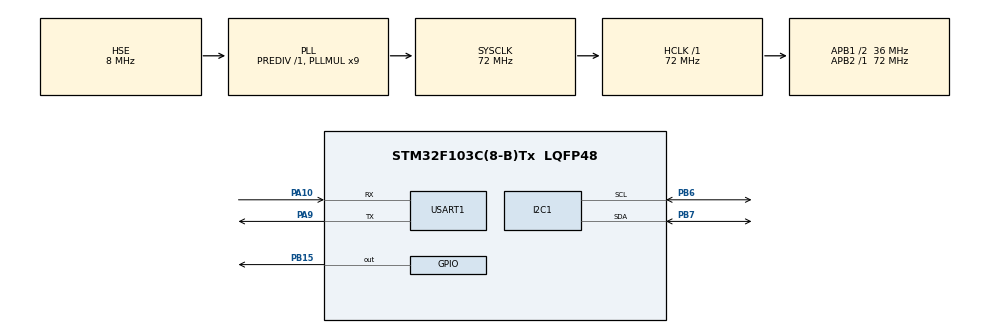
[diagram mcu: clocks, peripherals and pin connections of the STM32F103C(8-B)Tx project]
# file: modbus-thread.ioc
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Dma.I2C1_RX.0.Direction=DMA_PERIPH_TO_MEMORY
Dma.I2C1_RX.0.Instance=DMA1_Channel7
Dma.I2C1_RX.0.MemDataAlignment=DMA_MDATAALIGN_BYTE
Dma.I2C1_RX.0.MemInc=DMA_MINC_ENABLE
Dma.I2C1_RX.0.Mode=DMA_NORMAL
Dma.I2C1_RX.0.PeriphDataAlignment=DMA_PDATAALIGN_BYTE
Dma.I2C1_RX.0.PeriphInc=DMA_PINC_DISABLE
Dma.I2C1_RX.0.Priority=DMA_PRIORITY_LOW
Dma.I2C1_TX.1.Direction=DMA_MEMORY_TO_PERIPH
Dma.I2C1_TX.1.Instance=DMA1_Channel6
Dma.I2C1_TX.1.MemDataAlignment=DMA_MDATAALIGN_BYTE
Dma.I2C1_TX.1.MemInc=DMA_MINC_ENABLE
Dma.I2C1_TX.1.Mode=DMA_NORMAL
Dma.I2C1_TX.1.PeriphDataAlignment=DMA_PDATAALIGN_BYTE
Dma.I2C1_TX.1.PeriphInc=DMA_PINC_DISABLE
Dma.I2C1_TX.1.Priority=DMA_PRIORITY_LOW
Dma.Request0=I2C1_RX
Dma.Request1=I2C1_TX
Mcu.Family=STM32F1
Mcu.Name=STM32F103C(8-B)Tx
Mcu.Package=LQFP48
NVIC.DMA1_Channel6_IRQn=true\:0\:0\:false\:false\:true\:true\:false\:true\:true
NVIC.DMA1_Channel7_IRQn=true\:0\:0\:false\:false\:true\:true\:false\:true\:true
NVIC.I2C1_EV_IRQn=true\:0\:0\:false\:false\:true\:false\:true\:true\:true
NVIC.PriorityGroup=NVIC_PRIORITYGROUP_4
NVIC.TIM3_IRQn=true\:0\:0\:false\:false\:true\:false\:true\:true\:true
NVIC.USART1_IRQn=true\:1\:0\:true\:false\:true\:false\:true\:true\:true
PA10.Mode=Asynchronous
PA10.Signal=USART1_RX
PA13.Mode=Serial_Wire
PA13.Signal=SYS_JTMS-SWDIO
PA14.Mode=Serial_Wire
PA14.Signal=SYS_JTCK-SWCLK
PA9.Mode=Asynchronous
PA9.Signal=USART1_TX
PB15.Signal=GPIO_Output
PB6.Mode=I2C
PB6.Signal=I2C1_SCL
PB7.Mode=I2C
PB7.Signal=I2C1_SDA
PD0-OSC_IN.Mode=HSE-External-Oscillator
PD0-OSC_IN.Signal=RCC_OSC_IN
PD1-OSC_OUT.Mode=HSE-External-Oscillator
PD1-OSC_OUT.Signal=RCC_OSC_OUT
ProjectManager.HeapSize=0x200
ProjectManager.StackSize=0x400
ProjectManager.TargetToolchain=MDK-ARM V5.32
RCC.AHBFreq_Value=72000000
RCC.APB1CLKDivider=RCC_HCLK_DIV2
RCC.APB1Freq_Value=36000000
RCC.APB1TimFreq_Value=72000000
RCC.APB2Freq_Value=72000000
RCC.APB2TimFreq_Value=72000000
RCC.HCLKFreq_Value=72000000
RCC.PLLMUL=RCC_PLL_MUL9
RCC.PLLSourceVirtual=RCC_PLLSOURCE_HSE
RCC.SYSCLKFreq_VALUE=72000000
RCC.SYSCLKSource=RCC_SYSCLKSOURCE_PLLCLK
RCC.USBFreq_Value=72000000
RealThread.RT-Thread.3.1.5.RTOSJjdevice=true
RealThread.RT-Thread.3.1.5.RTOSJjkernel=true
RealThread.RT-Thread.3.1.5.RTOSJjshell=true
TIM3.Period=35
TIM3.Prescaler=3600-1
USART1.VirtualMode=VM_ASYNC
VP_RealThread.RT-Thread_VS_RTOSJjdevice_3.1.5_3.1.5.Mode=RTOSJjdevice
VP_RealThread.RT-Thread_VS_RTOSJjkernel_3.1.5_3.1.5.Mode=RTOSJjkernel
VP_RealThread.RT-Thread_VS_RTOSJjshell_3.1.5_3.1.5.Mode=RTOSJjshell
VP_TIM3_VS_ClockSourceINT.Mode=Internal
board=custom

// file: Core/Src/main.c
/* USER CODE BEGIN Header */
/**
  ******************************************************************************
  * @file           : main.c
  * @brief          : Main program body
  ******************************************************************************
  * @attention
  *
  * Copyright (c) 2022 STMicroelectronics.
  * All rights reserved.
  *
  * This software is licensed under terms that can be found in the LICENSE file
  * in the root directory of this software component.
  * If no LICENSE file comes with this software, it is provided AS-IS.
  *
  ******************************************************************************
  */
/* USER CODE END Header */
#include "main.h"
#include "dma.h"
#include "i2c.h"
#include "tim.h"
#include "usart.h"
#include "gpio.h"
#include "mb.h"
#include "mbport.h"
/* USER CODE BEGIN Includes */
#include <stdio.h>
#include "AHT20-21_DEMO_V1_3.h"
/* USER CODE END Includes */

/* USER CODE BEGIN PTD */
extern void MX_RT_Thread_Init(void);
extern void MX_RT_Thread_Process(void);
/* USER CODE END PTD */

void SystemClock_Config(void);

int main(void)
{

  /* MCU Configuration--------------------------------------------------------*/

  /* Reset of all peripherals, Initializes the Flash interface and the Systick. */
  HAL_Init();

  /* Configure the system clock */
  SystemClock_Config();

  /* Initialize all configured peripherals */
  MX_GPIO_Init();
  MX_DMA_Init();
  MX_I2C1_Init();
  MX_USART1_UART_Init();
  MX_TIM3_Init();
	AHT20_Init();
	eMBInit( MB_RTU, 0x01, 1, 115200, MB_PAR_NONE);//初始化modbus，走modbusRTU，从站地址为0x01，端口为1。
	eMBEnable(  );//使能modbus
  /* USER CODE BEGIN 2 */
 MX_RT_Thread_Init();

  /* USER CODE END 2 */

  /* Infinite loop */
  while (1)
  {
		( void )eMBPoll(  );//启动modbus侦听
  }
}

void SystemClock_Config(void)
{
  RCC_OscInitTypeDef RCC_OscInitStruct = {0};
  RCC_ClkInitTypeDef RCC_ClkInitStruct = {0};

  /** Initializes the RCC Oscillators according to the specified parameters
  * in the RCC_OscInitTypeDef structure.
  */
  RCC_OscInitStruct.OscillatorType = RCC_OSCILLATORTYPE_HSE;
  RCC_OscInitStruct.HSEState = RCC_HSE_ON;
  RCC_OscInitStruct.HSEPredivValue = RCC_HSE_PREDIV_DIV1;
  RCC_OscInitStruct.HSIState = RCC_HSI_ON;
  RCC_OscInitStruct.PLL.PLLState = RCC_PLL_ON;
  RCC_OscInitStruct.PLL.PLLSource = RCC_PLLSOURCE_HSE;
  RCC_OscInitStruct.PLL.PLLMUL = RCC_PLL_MUL9;
  if (HAL_RCC_OscConfig(&RCC_OscInitStruct) != HAL_OK)
  {
    Error_Handler();
  }

  /** Initializes the CPU, AHB and APB buses clocks
  */
  RCC_ClkInitStruct.ClockType = RCC_CLOCKTYPE_HCLK|RCC_CLOCKTYPE_SYSCLK
                              |RCC_CLOCKTYPE_PCLK1|RCC_CLOCKTYPE_PCLK2;
  RCC_ClkInitStruct.SYSCLKSource = RCC_SYSCLKSOURCE_PLLCLK;
  RCC_ClkInitStruct.AHBCLKDivider = RCC_SYSCLK_DIV1;
  RCC_ClkInitStruct.APB1CLKDivider = RCC_HCLK_DIV2;
  RCC_ClkInitStruct.APB2CLKDivider = RCC_HCLK_DIV1;

  if (HAL_RCC_ClockConfig(&RCC_ClkInitStruct, FLASH_LATENCY_2) != HAL_OK)
  {
    Error_Handler();
  }
}

void Error_Handler(void)
{
  __disable_irq();
  while (1)
  {
  }
}
